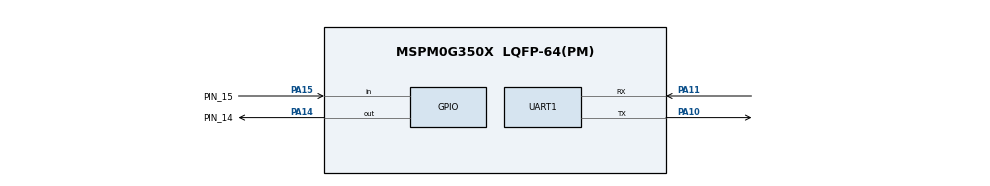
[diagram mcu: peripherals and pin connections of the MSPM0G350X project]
/**
 * @cliArgs --device "MSPM0G350X" --package "LQFP-64(PM)" --part "Default" --product "mspm0_sdk@2.00.01.00"
 * @versions {"tool":"1.20.0+3587"}
 */

/**
 * Import the modules used in this configuration.
 */
const GPIO    = scripting.addModule("/ti/driverlib/GPIO", {}, false);
const GPIO1   = GPIO.addInstance();
const GPIO2   = GPIO.addInstance();
const SYSCTL  = scripting.addModule("/ti/driverlib/SYSCTL");
const SYSTICK = scripting.addModule("/ti/driverlib/SYSTICK");
const TIMER   = scripting.addModule("/ti/driverlib/TIMER", {}, false);
const TIMER1  = TIMER.addInstance();
const UART    = scripting.addModule("/ti/driverlib/UART", {}, false);
const UART1   = UART.addInstance();

/**
 * Write custom configuration values to the imported modules.
 */
const divider9       = system.clockTree["UDIV"];
divider9.divideValue = 2;

const gate7  = system.clockTree["MFCLKGATE"];
gate7.enable = true;

const multiplier2         = system.clockTree["PLL_QDIV"];
multiplier2.multiplyValue = 4;

const mux2       = system.clockTree["CANCLKMUX"];
mux2.inputSelect = "CANCLKMUX_PLLCLK1_OUT";

const mux4       = system.clockTree["EXHFMUX"];
mux4.inputSelect = "EXHFMUX_XTAL";

const mux8       = system.clockTree["HSCLKMUX"];
mux8.inputSelect = "HSCLKMUX_SYSPLL0";

const mux10       = system.clockTree["MFPCLKMUX"];
mux10.inputSelect = "MFPCLKMUX_HFCLK";

const mux12       = system.clockTree["SYSPLLMUX"];
mux12.inputSelect = "zSYSPLLMUX_HFCLK";

const pinFunction4     = system.clockTree["HFXT"];
pinFunction4.inputFreq = 40;
pinFunction4.enable    = true;

GPIO1.$name                              = "GPIO_GRP_0";
GPIO1.port                               = "PORTA";
GPIO1.associatedPins[0].internalResistor = "PULL_DOWN";
GPIO1.associatedPins[0].interruptEn      = true;
GPIO1.associatedPins[0].polarity         = "RISE";
GPIO1.associatedPins[0].$name            = "PIN_14";
GPIO1.associatedPins[0].assignedPin      = "14";
GPIO1.associatedPins[0].pin.$assign      = "PA14";

const Board = scripting.addModule("/ti/driverlib/Board", {}, false);

GPIO2.port                                = "PORTA";
GPIO2.$name                               = "GPIO_GRP_15";
GPIO2.associatedPins[0].subChanID         = 1;
GPIO2.associatedPins[0].direction         = "INPUT";
GPIO2.associatedPins[0].internalResistor  = "PULL_DOWN";
GPIO2.associatedPins[0].interruptEn       = true;
GPIO2.associatedPins[0].polarity          = "RISE";
GPIO2.associatedPins[0].$name             = "PIN_15";
GPIO2.associatedPins[0].interruptPriority = "1";
GPIO2.associatedPins[0].pin.$assign       = "PA15";

SYSCTL.forceDefaultClkConfig = true;
SYSCTL.clockTreeEn           = true;

SYSTICK.periodEnable  = true;
SYSTICK.systickEnable = true;
SYSTICK.period        = 16777216;

TIMER1.$name              = "TIMEG_0";
TIMER1.timerClkDiv        = 8;
TIMER1.timerClkPrescale   = 100;
TIMER1.timerPeriod        = "10 ms";
TIMER1.interrupts         = ["LOAD"];
TIMER1.peripheral.$assign = "TIMG0";

UART1.$name                    = "UART_0";
UART1.uartClkSrc               = "MFCLK";
UART1.enabledInterrupts        = ["RX"];
UART1.peripheral.$assign       = "UART0";
UART1.peripheral.rxPin.$assign = "PA11";
UART1.peripheral.txPin.$assign = "PA10";
UART1.txPinConfig.$name        = "ti_driverlib_gpio_GPIOPinGeneric0";
UART1.rxPinConfig.$name        = "ti_driverlib_gpio_GPIOPinGeneric1";

/**
 * Pinmux solution for unlocked pins/peripherals. This ensures that minor changes to the automatic solver in a future
 * version of the tool will not impact the pinmux you originally saw.  These lines can be completely deleted in order to
 * re-solve from scratch.
 */
pinFunction4.peripheral.$suggestSolution           = "SYSCTL";
pinFunction4.peripheral.hfxInPin.$suggestSolution  = "PA5";
pinFunction4.peripheral.hfxOutPin.$suggestSolution = "PA6";
Board.peripheral.$suggestSolution                  = "DEBUGSS";
Board.peripheral.swclkPin.$suggestSolution         = "PA20";
Board.peripheral.swdioPin.$suggestSolution         = "PA19";
